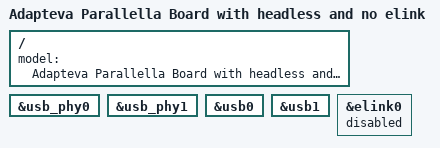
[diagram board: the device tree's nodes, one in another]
/*
 * Copyright (c) 2016 Adapteva
 *
 * This software is licensed under the terms of the GNU General Public
 * License version 2, as published by the Free Software Foundation, and
 * may be copied, distributed, and modified under those terms.
 *
 * This program is distributed in the hope that it will be useful,
 * but WITHOUT ANY WARRANTY; without even the implied warranty of
 * MERCHANTABILITY or FITNESS FOR A PARTICULAR PURPOSE.  See the
 * GNU General Public License for more details.
 */
/dts-v1/;
#include "zynq-parallella1.dtsi"

/ {
	model = "Adapteva Parallella Board with headless and no elink";
};

&usb_phy0 {
	status = "okay";
};

&usb_phy1 {
	status = "okay";
};

&usb0 {
	status = "okay";
};

&usb1 {
	status = "okay";
};

&elink0 {
	status = "disabled";
};
